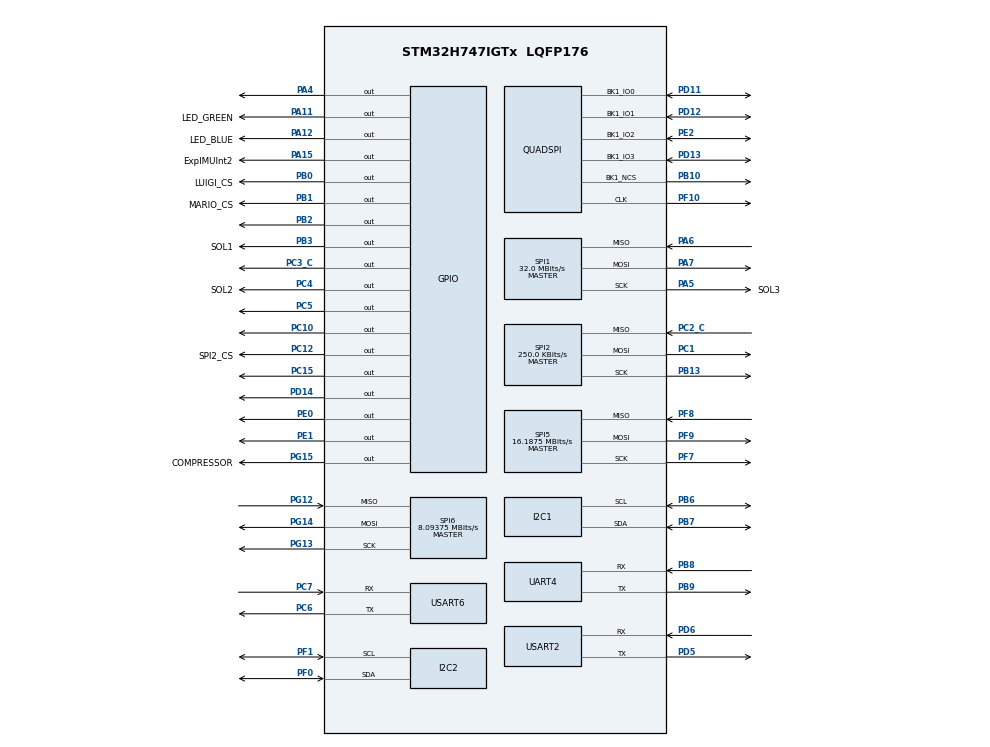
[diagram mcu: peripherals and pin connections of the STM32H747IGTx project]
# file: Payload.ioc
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CortexM4.IPs=BDMA,CORTEX_M4\:I,DEBUG,DMA,FATFS_M4\:I,FREERTOS_M4\:I,GPIO,IWDG2\:I,MDMA,NVIC2\:I,OPENAMP_M4\:I,PDM2PCM_M4\:I,PWR,RCC,RESMGR_UTILITY,SYS_M4\:I,USB_DEVICE_M4\:I,USB_HOST_M4\:I,VREFBUF,WWDG2\:I,QUADSPI,CRC
CortexM7.IPs=BDMA\:I,CORTEX_M7\:I,DEBUG\:I,DMA\:I,FATFS_M7\:I,FREERTOS_M7\:I,GPIO\:I,IWDG1\:I,MDMA\:I,NVIC1\:I,OPENAMP_M7\:I,PDM2PCM_M7\:I,PWR\:I,RCC\:I,RESMGR_UTILITY\:I,SYS\:I,USB_DEVICE_M7\:I,USB_HOST_M7\:I,VREFBUF\:I,WWDG1\:I,LPUART1\:I,USART2\:I,USART3\:I,USART6\:I,UART4\:I,UART5\:I,UART7\:I,SPI1\:I,SPI2\:I,SPI3\:I,SPI4\:I,SPI6\:I,QUADSPI\:I,I2C1\:I,I2C2\:I,I2C3\:I,SPI5\:I,CRC\:I,TIM1\:I
CortexM7.Pins=PC15-OSC32_OUT (OSC32_OUT),PC3_C,PA4,PC4,PC5,PB0,PB1,PB2,PD14,PA11,PA12,PA15 (JTDI),PC10,PC12,PG15,PB3 (JTDO/TRACESWO),PB4 (NJTRST),PB5,PE0,PE1
FREERTOS_M7.Tasks01=defaultTask,0,192,StartDefaultTask,Default,NULL,Dynamic,NULL,NULL
FREERTOS_M7.configMINIMAL_STACK_SIZE=192
FREERTOS_M7.configTOTAL_HEAP_SIZE=96000
FREERTOS_M7.configUSE_NEWLIB_REENTRANT=1
FREERTOS_M7.configUSE_TIMERS=1
I2C1.Timing=0x00807DBE
I2C2.Timing=0x00807DBE
Mcu.Family=STM32H7
Mcu.Name=STM32H747IGTx
Mcu.Package=LQFP176
NVIC1.PriorityGroup=NVIC_PRIORITYGROUP_4
NVIC1.TIM1_UP_IRQn=true\:15\:0\:false\:false\:true\:false\:false\:true\:true
NVIC1.TimeBase=TIM1_UP_IRQn
NVIC1.TimeBaseIP=TIM1
NVIC1.USART6_IRQn=true\:5\:0\:false\:false\:true\:true\:true\:true\:true
NVIC2.PriorityGroup=NVIC_PRIORITYGROUP_4
PA11.GPIO_Label=LED_GREEN
PA11.PinAttribute=CortexM7
PA11.Signal=GPIO_Output
PA12.GPIO_Label=LED_BLUE
PA12.PinAttribute=CortexM7
PA12.Signal=GPIO_Output
PA13\ (JTMS/SWDIO).PinAttribute=CortexM7
PA13\ (JTMS/SWDIO).Signal=DEBUG_JTMS-SWDIO
PA14\ (JTCK/SWCLK).PinAttribute=CortexM7
PA14\ (JTCK/SWCLK).Signal=DEBUG_JTCK-SWCLK
PA15\ (JTDI).GPIO_Label=ExpIMUInt2
PA15\ (JTDI).PinAttribute=CortexM7
PA15\ (JTDI).Signal=GPIO_Output
PA4.PinAttribute=CortexM7
PA4.Signal=GPIO_Output
PA5.GPIO_Label=SOL3
PA5.Mode=Full_Duplex_Master
PA5.PinAttribute=CortexM7
PA5.Signal=SPI1_SCK
PA6.Mode=Full_Duplex_Master
PA6.PinAttribute=CortexM7
PA6.Signal=SPI1_MISO
PA7.Mode=Full_Duplex_Master
PA7.PinAttribute=CortexM7
PA7.Signal=SPI1_MOSI
PB0.GPIO_Label=LUIGI_CS
PB0.PinAttribute=CortexM7
PB0.PinState=GPIO_PIN_SET
PB0.Signal=GPIO_Output
PB1.GPIO_Label=MARIO_CS
PB1.PinAttribute=CortexM7
PB1.PinState=GPIO_PIN_SET
PB1.Signal=GPIO_Output
PB10.Mode=Single Bank 1
PB10.PinAttribute=CortexM7
PB10.Signal=QUADSPI_BK1_NCS
PB13.Mode=Full_Duplex_Master
PB13.PinAttribute=CortexM7
PB13.Signal=SPI2_SCK
PB2.PinAttribute=CortexM7
PB2.Signal=GPIO_Output
PB3\ (JTDO/TRACESWO).GPIO_Label=SOL1
PB3\ (JTDO/TRACESWO).PinAttribute=CortexM7
PB3\ (JTDO/TRACESWO).Signal=GPIO_Output
PB6.Mode=I2C
PB6.PinAttribute=CortexM7
PB6.Signal=I2C1_SCL
PB7.Mode=I2C
PB7.PinAttribute=CortexM7
PB7.Signal=I2C1_SDA
PB8.Mode=Asynchronous
PB8.PinAttribute=CortexM7
PB8.Signal=UART4_RX
PB9.Mode=Asynchronous
PB9.PinAttribute=CortexM7
PB9.Signal=UART4_TX
PC1.Mode=Full_Duplex_Master
PC1.PinAttribute=CortexM7
PC1.Signal=SPI2_MOSI
PC10.PinAttribute=CortexM7
PC10.Signal=GPIO_Output
PC12.GPIO_Label=SPI2_CS
PC12.PinAttribute=CortexM7
PC12.Signal=GPIO_Output
PC15-OSC32_OUT\ (OSC32_OUT).PinAttribute=CortexM7
PC15-OSC32_OUT\ (OSC32_OUT).Signal=GPIO_Output
PC2_C.Mode=Full_Duplex_Master
PC2_C.PinAttribute=CortexM7
PC2_C.Signal=SPI2_MISO
PC3_C.PinAttribute=CortexM7
PC3_C.Signal=GPIO_Output
PC4.GPIO_Label=SOL2
PC4.PinAttribute=CortexM7
PC4.Signal=GPIO_Output
PC5.PinAttribute=CortexM7
PC5.Signal=GPIO_Output
PC6.Mode=Asynchronous
PC6.PinAttribute=CortexM7
PC6.Signal=USART6_TX
PC7.Mode=Asynchronous
PC7.PinAttribute=CortexM7
PC7.Signal=USART6_RX
PD11.Mode=Single Bank 1
PD11.PinAttribute=CortexM7
PD11.Signal=QUADSPI_BK1_IO0
PD12.Mode=Single Bank 1
PD12.PinAttribute=CortexM7
PD12.Signal=QUADSPI_BK1_IO1
PD13.Mode=Single Bank 1
PD13.PinAttribute=CortexM7
PD13.Signal=QUADSPI_BK1_IO3
PD14.PinAttribute=CortexM7
PD14.Signal=GPIO_Output
PD5.Mode=Asynchronous
PD5.PinAttribute=CortexM7
PD5.Signal=USART2_TX
PD6.Mode=Asynchronous
PD6.PinAttribute=CortexM7
PD6.Signal=USART2_RX
PE0.PinAttribute=CortexM7
PE0.Signal=GPIO_Output
PE1.PinAttribute=CortexM7
PE1.Signal=GPIO_Output
PE10.PinAttribute=CortexM7
PE10.Signal=QUADSPI_BK2_IO3
PE2.Mode=Single Bank 1
PE2.PinAttribute=CortexM7
PE2.Signal=QUADSPI_BK1_IO2
PE7.PinAttribute=CortexM7
PE7.Signal=QUADSPI_BK2_IO0
PE8.PinAttribute=CortexM7
PE8.Signal=QUADSPI_BK2_IO1
PE9.PinAttribute=CortexM7
PE9.Signal=QUADSPI_BK2_IO2
PF0.Mode=I2C
PF0.PinAttribute=CortexM7
PF0.Signal=I2C2_SDA
PF1.Mode=I2C
PF1.PinAttribute=CortexM7
PF1.Signal=I2C2_SCL
PF10.Mode=Single Bank 1
PF10.PinAttribute=CortexM7
PF10.Signal=QUADSPI_CLK
PF7.Mode=Full_Duplex_Master
PF7.PinAttribute=CortexM7
PF7.Signal=SPI5_SCK
PF8.Mode=Full_Duplex_Master
PF8.PinAttribute=CortexM7
PF8.Signal=SPI5_MISO
PF9.Mode=Full_Duplex_Master
PF9.PinAttribute=CortexM7
PF9.Signal=SPI5_MOSI
PG12.Mode=Full_Duplex_Master
PG12.PinAttribute=CortexM7
PG12.Signal=SPI6_MISO
PG13.Mode=Full_Duplex_Master
PG13.PinAttribute=CortexM7
PG13.Signal=SPI6_SCK
PG14.Mode=Full_Duplex_Master
PG14.PinAttribute=CortexM7
PG14.Signal=SPI6_MOSI
PG15.GPIO_Label=COMPRESSOR
PG15.PinAttribute=CortexM7
PG15.Signal=GPIO_Output
ProjectManager.HeapSize=M4-0x200,M7-0x200
ProjectManager.StackSize=M4-0x400,M7-0x400
ProjectManager.TargetToolchain=STM32CubeIDE
RCC.ADCFreq_Value=129000000
RCC.APB1Freq_Value=32375000
RCC.APB2Freq_Value=32375000
RCC.APB3Freq_Value=32375000
RCC.APB4Freq_Value=32375000
RCC.CortexFreq_Value=259000000
RCC.D1PPRE=RCC_APB3_DIV2
RCC.D2PPRE1=RCC_APB1_DIV2
RCC.D2PPRE2=RCC_APB2_DIV2
RCC.D3PPRE=RCC_APB4_DIV2
RCC.DIVM1=4
RCC.DIVN1=32
RCC.HCLKFreq_Value=64750000
RCC.HPRE=RCC_HCLK_DIV4
RCC.PLL1_VCI_Range-AdvancedSettings=RCC_PLL1VCIRANGE_1
RCC.PLL2FRACN=0
RCC.PLL3FRACN=0
RCC.PLLFRACN=3072
RCC.SPI123CLockSelection=RCC_SPI123CLKSOURCE_CLKP
RCC.SYSCLKFreq_VALUE=259000000
RCC.SYSCLKSource=RCC_SYSCLKSOURCE_PLLCLK
RCC.SupplySource=PWR_LDO_SUPPLY
RCC.USBFreq_Value=259000000
SPI1.BaudRatePrescaler=SPI_BAUDRATEPRESCALER_2
SPI1.CalculateBaudRate=32.0 MBits/s
SPI1.Direction=SPI_DIRECTION_2LINES
SPI1.Mode=SPI_MODE_MASTER
SPI1.VirtualType=VM_MASTER
SPI2.BaudRatePrescaler=SPI_BAUDRATEPRESCALER_256
SPI2.CLKPhase=SPI_PHASE_2EDGE
SPI2.CLKPolarity=SPI_POLARITY_HIGH
SPI2.CalculateBaudRate=250.0 KBits/s
SPI2.DataSize=SPI_DATASIZE_8BIT
SPI2.Direction=SPI_DIRECTION_2LINES
SPI2.Mode=SPI_MODE_MASTER
SPI2.VirtualType=VM_MASTER
SPI5.CalculateBaudRate=16.1875 MBits/s
SPI5.Direction=SPI_DIRECTION_2LINES
SPI5.Mode=SPI_MODE_MASTER
SPI5.VirtualType=VM_MASTER
SPI6.BaudRatePrescaler=SPI_BAUDRATEPRESCALER_4
SPI6.CLKPhase=SPI_PHASE_2EDGE
SPI6.CLKPolarity=SPI_POLARITY_HIGH
SPI6.CalculateBaudRate=8.09375 MBits/s
SPI6.DataSize=SPI_DATASIZE_8BIT
SPI6.Direction=SPI_DIRECTION_2LINES
SPI6.Mode=SPI_MODE_MASTER
SPI6.VirtualType=VM_MASTER
SYS.userName=SYS_M7
USART2.VirtualMode-Asynchronous=VM_ASYNC
USART6.VirtualMode-Asynchronous=VM_ASYNC
VP_CRC_VS_CRC.Mode=CRC_Activate
VP_FREERTOS_M7_VS_CMSIS_V1.Mode=CMSIS_V1
VP_SYS_M4_VS_Systick.Mode=SysTick
VP_SYS_VS_tim1.Mode=TIM1
board=custom

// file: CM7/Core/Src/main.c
/* USER CODE BEGIN Header */
/**
  ******************************************************************************
  * @file           : main.c
  * @brief          : Main program body
  ******************************************************************************
  * @attention
  *
  * Copyright (c) 2024 STMicroelectronics.
  * All rights reserved.
  *
  * This software is licensed under terms that can be found in the LICENSE file
  * in the root directory of this software component.
  * If no LICENSE file comes with this software, it is provided AS-IS.
  *
  ******************************************************************************
  */
/* USER CODE END Header */
#include "main.h"
#include "cmsis_os.h"

/* USER CODE BEGIN Includes */
#include "RunInterface.hpp"
/* USER CODE END Includes */

/* USER CODE BEGIN PD */

#ifndef HSEM_ID_0
#define HSEM_ID_0 (0U) /* HW semaphore 0*/
#endif

/* USER CODE END PD */

CRC_HandleTypeDef hcrc;

I2C_HandleTypeDef hi2c1;
I2C_HandleTypeDef hi2c2;

QSPI_HandleTypeDef hqspi;

SPI_HandleTypeDef hspi1;
SPI_HandleTypeDef hspi2;
SPI_HandleTypeDef hspi5;
SPI_HandleTypeDef hspi6;

UART_HandleTypeDef huart4;
UART_HandleTypeDef huart2;

osThreadId defaultTaskHandle;

void SystemClock_Config(void);
void PeriphCommonClock_Config(void);
static void MX_GPIO_Init(void);
static void MX_QUADSPI_Init(void);
static void MX_SPI1_Init(void);
static void MX_I2C1_Init(void);
static void MX_I2C2_Init(void);
static void MX_SPI2_Init(void);
static void MX_SPI5_Init(void);
static void MX_USART2_UART_Init(void);
static void MX_UART4_Init(void);
static void MX_USART6_UART_Init(void);
static void MX_SPI6_Init(void);
static void MX_CRC_Init(void);
void StartDefaultTask(void const * argument);

int main(void)
{

/* USER CODE BEGIN Boot_Mode_Sequence_0 */
  int32_t timeout;
/* USER CODE END Boot_Mode_Sequence_0 */

/* USER CODE BEGIN Boot_Mode_Sequence_1 */
  /* Wait until CPU2 boots and enters in stop mode or timeout*/
  timeout = 0xFFFF;
  while((__HAL_RCC_GET_FLAG(RCC_FLAG_D2CKRDY) != RESET) && (timeout-- > 0));
  if ( timeout < 0 )
  {
  Error_Handler();
  }
/* USER CODE END Boot_Mode_Sequence_1 */
  /* MCU Configuration--------------------------------------------------------*/

  /* Reset of all peripherals, Initializes the Flash interface and the Systick. */
  HAL_Init();

  /* Configure the system clock */
  SystemClock_Config();

/* Configure the peripherals common clocks */
  PeriphCommonClock_Config();
/* USER CODE BEGIN Boot_Mode_Sequence_2 */
/* When system initialization is finished, Cortex-M7 will release Cortex-M4 by means of
HSEM notification */
/*HW semaphore Clock enable*/
__HAL_RCC_HSEM_CLK_ENABLE();
/*Take HSEM */
HAL_HSEM_FastTake(HSEM_ID_0);
/*Release HSEM in order to notify the CPU2(CM4)*/
HAL_HSEM_Release(HSEM_ID_0,0);
/* wait until CPU2 wakes up from stop mode */
timeout = 0xFFFF;
while((__HAL_RCC_GET_FLAG(RCC_FLAG_D2CKRDY) == RESET) && (timeout-- > 0));
if ( timeout < 0 )
{
Error_Handler();
}
/* USER CODE END Boot_Mode_Sequence_2 */

  /* Initialize all configured peripherals */
  MX_GPIO_Init();
  MX_QUADSPI_Init();
  MX_SPI1_Init();
  MX_I2C1_Init();
  MX_I2C2_Init();
  MX_SPI2_Init();
  MX_SPI5_Init();
  MX_USART2_UART_Init();
  MX_UART4_Init();
  MX_USART6_UART_Init();
  MX_SPI6_Init();
  MX_CRC_Init();
  /* USER CODE BEGIN 2 */
  run_interface();
  #if 0
  /* USER CODE END 2 */

  /* Create the thread(s) */
  /* definition and creation of defaultTask */
  osThreadDef(defaultTask, StartDefaultTask, osPriorityNormal, 0, 192);
  defaultTaskHandle = osThreadCreate(osThread(defaultTask), NULL);

  /* Start scheduler */
  osKernelStart();

  /* We should never get here as control is now taken by the scheduler */

  /* Infinite loop */
  while (1)
  {

    /* USER CODE BEGIN 3 */
  }
#endif
  /* USER CODE END 3 */
}

void SystemClock_Config(void)
{
  RCC_OscInitTypeDef RCC_OscInitStruct = {0};
  RCC_ClkInitTypeDef RCC_ClkInitStruct = {0};

  /** Supply configuration update enable
  */
  HAL_PWREx_ConfigSupply(PWR_LDO_SUPPLY);

  /** Configure the main internal regulator output voltage
  */
  __HAL_PWR_VOLTAGESCALING_CONFIG(PWR_REGULATOR_VOLTAGE_SCALE2);

  while(!__HAL_PWR_GET_FLAG(PWR_FLAG_VOSRDY)) {}

  /** Initializes the RCC Oscillators according to the specified parameters
  * in the RCC_OscInitTypeDef structure.
  */
  RCC_OscInitStruct.OscillatorType = RCC_OSCILLATORTYPE_HSI;
  RCC_OscInitStruct.HSIState = RCC_HSI_DIV1;
  RCC_OscInitStruct.HSICalibrationValue = RCC_HSICALIBRATION_DEFAULT;
  RCC_OscInitStruct.PLL.PLLState = RCC_PLL_ON;
  RCC_OscInitStruct.PLL.PLLSource = RCC_PLLSOURCE_HSI;
  RCC_OscInitStruct.PLL.PLLM = 4;
  RCC_OscInitStruct.PLL.PLLN = 32;
  RCC_OscInitStruct.PLL.PLLP = 2;
  RCC_OscInitStruct.PLL.PLLQ = 2;
  RCC_OscInitStruct.PLL.PLLR = 2;
  RCC_OscInitStruct.PLL.PLLRGE = RCC_PLL1VCIRANGE_3;
  RCC_OscInitStruct.PLL.PLLVCOSEL = RCC_PLL1VCOWIDE;
  RCC_OscInitStruct.PLL.PLLFRACN = 3072;
  if (HAL_RCC_OscConfig(&RCC_OscInitStruct) != HAL_OK)
  {
    Error_Handler();
  }

  /** Initializes the CPU, AHB and APB buses clocks
  */
  RCC_ClkInitStruct.ClockType = RCC_CLOCKTYPE_HCLK|RCC_CLOCKTYPE_SYSCLK
                              |RCC_CLOCKTYPE_PCLK1|RCC_CLOCKTYPE_PCLK2
                              |RCC_CLOCKTYPE_D3PCLK1|RCC_CLOCKTYPE_D1PCLK1;
  RCC_ClkInitStruct.SYSCLKSource = RCC_SYSCLKSOURCE_PLLCLK;
  RCC_ClkInitStruct.SYSCLKDivider = RCC_SYSCLK_DIV1;
  RCC_ClkInitStruct.AHBCLKDivider = RCC_HCLK_DIV4;
  RCC_ClkInitStruct.APB3CLKDivider = RCC_APB3_DIV2;
  RCC_ClkInitStruct.APB1CLKDivider = RCC_APB1_DIV2;
  RCC_ClkInitStruct.APB2CLKDivider = RCC_APB2_DIV2;
  RCC_ClkInitStruct.APB4CLKDivider = RCC_APB4_DIV2;

  if (HAL_RCC_ClockConfig(&RCC_ClkInitStruct, FLASH_LATENCY_1) != HAL_OK)
  {
    Error_Handler();
  }
}

void PeriphCommonClock_Config(void)
{
  RCC_PeriphCLKInitTypeDef PeriphClkInitStruct = {0};

  /** Initializes the peripherals clock
  */
  PeriphClkInitStruct.PeriphClockSelection = RCC_PERIPHCLK_CKPER;
  PeriphClkInitStruct.CkperClockSelection = RCC_CLKPSOURCE_HSI;
  if (HAL_RCCEx_PeriphCLKConfig(&PeriphClkInitStruct) != HAL_OK)
  {
    Error_Handler();
  }
}

static void MX_CRC_Init(void)
{

  hcrc.Instance = CRC;
  hcrc.Init.DefaultPolynomialUse = DEFAULT_POLYNOMIAL_ENABLE;
  hcrc.Init.DefaultInitValueUse = DEFAULT_INIT_VALUE_ENABLE;
  hcrc.Init.InputDataInversionMode = CRC_INPUTDATA_INVERSION_NONE;
  hcrc.Init.OutputDataInversionMode = CRC_OUTPUTDATA_INVERSION_DISABLE;
  hcrc.InputDataFormat = CRC_INPUTDATA_FORMAT_BYTES;
  if (HAL_CRC_Init(&hcrc) != HAL_OK)
  {
    Error_Handler();
  }

}

static void MX_I2C1_Init(void)
{

  hi2c1.Instance = I2C1;
  hi2c1.Init.Timing = 0x00807DBE;
  hi2c1.Init.OwnAddress1 = 0;
  hi2c1.Init.AddressingMode = I2C_ADDRESSINGMODE_7BIT;
  hi2c1.Init.DualAddressMode = I2C_DUALADDRESS_DISABLE;
  hi2c1.Init.OwnAddress2 = 0;
  hi2c1.Init.OwnAddress2Masks = I2C_OA2_NOMASK;
  hi2c1.Init.GeneralCallMode = I2C_GENERALCALL_DISABLE;
  hi2c1.Init.NoStretchMode = I2C_NOSTRETCH_DISABLE;
  if (HAL_I2C_Init(&hi2c1) != HAL_OK)
  {
    Error_Handler();
  }

  /** Configure Analogue filter
  */
  if (HAL_I2CEx_ConfigAnalogFilter(&hi2c1, I2C_ANALOGFILTER_ENABLE) != HAL_OK)
  {
    Error_Handler();
  }

  /** Configure Digital filter
  */
  if (HAL_I2CEx_ConfigDigitalFilter(&hi2c1, 0) != HAL_OK)
  {
    Error_Handler();
  }

}

static void MX_I2C2_Init(void)
{

  hi2c2.Instance = I2C2;
  hi2c2.Init.Timing = 0x00807DBE;
  hi2c2.Init.OwnAddress1 = 0;
  hi2c2.Init.AddressingMode = I2C_ADDRESSINGMODE_7BIT;
  hi2c2.Init.DualAddressMode = I2C_DUALADDRESS_DISABLE;
  hi2c2.Init.OwnAddress2 = 0;
  hi2c2.Init.OwnAddress2Masks = I2C_OA2_NOMASK;
  hi2c2.Init.GeneralCallMode = I2C_GENERALCALL_DISABLE;
  hi2c2.Init.NoStretchMode = I2C_NOSTRETCH_DISABLE;
  if (HAL_I2C_Init(&hi2c2) != HAL_OK)
  {
    Error_Handler();
  }

  /** Configure Analogue filter
  */
  if (HAL_I2CEx_ConfigAnalogFilter(&hi2c2, I2C_ANALOGFILTER_ENABLE) != HAL_OK)
  {
    Error_Handler();
  }

  /** Configure Digital filter
  */
  if (HAL_I2CEx_ConfigDigitalFilter(&hi2c2, 0) != HAL_OK)
  {
    Error_Handler();
  }

}

static void MX_QUADSPI_Init(void)
{

  /* QUADSPI parameter configuration*/
  hqspi.Instance = QUADSPI;
  hqspi.Init.ClockPrescaler = 255;
  hqspi.Init.FifoThreshold = 1;
  hqspi.Init.SampleShifting = QSPI_SAMPLE_SHIFTING_NONE;
  hqspi.Init.FlashSize = 1;
  hqspi.Init.ChipSelectHighTime = QSPI_CS_HIGH_TIME_1_CYCLE;
  hqspi.Init.ClockMode = QSPI_CLOCK_MODE_0;
  hqspi.Init.FlashID = QSPI_FLASH_ID_1;
  hqspi.Init.DualFlash = QSPI_DUALFLASH_DISABLE;
  if (HAL_QSPI_Init(&hqspi) != HAL_OK)
  {
    Error_Handler();
  }

}

static void MX_SPI1_Init(void)
{

  /* SPI1 parameter configuration*/
  hspi1.Instance = SPI1;
  hspi1.Init.Mode = SPI_MODE_MASTER;
  hspi1.Init.Direction = SPI_DIRECTION_2LINES;
  hspi1.Init.DataSize = SPI_DATASIZE_4BIT;
  hspi1.Init.CLKPolarity = SPI_POLARITY_LOW;
  hspi1.Init.CLKPhase = SPI_PHASE_1EDGE;
  hspi1.Init.NSS = SPI_NSS_SOFT;
  hspi1.Init.BaudRatePrescaler = SPI_BAUDRATEPRESCALER_2;
  hspi1.Init.FirstBit = SPI_FIRSTBIT_MSB;
  hspi1.Init.TIMode = SPI_TIMODE_DISABLE;
  hspi1.Init.CRCCalculation = SPI_CRCCALCULATION_DISABLE;
  hspi1.Init.CRCPolynomial = 0x0;
  hspi1.Init.NSSPMode = SPI_NSS_PULSE_ENABLE;
  hspi1.Init.NSSPolarity = SPI_NSS_POLARITY_LOW;
  hspi1.Init.FifoThreshold = SPI_FIFO_THRESHOLD_01DATA;
  hspi1.Init.TxCRCInitializationPattern = SPI_CRC_INITIALIZATION_ALL_ZERO_PATTERN;
  hspi1.Init.RxCRCInitializationPattern = SPI_CRC_INITIALIZATION_ALL_ZERO_PATTERN;
  hspi1.Init.MasterSSIdleness = SPI_MASTER_SS_IDLENESS_00CYCLE;
  hspi1.Init.MasterInterDataIdleness = SPI_MASTER_INTERDATA_IDLENESS_00CYCLE;
  hspi1.Init.MasterReceiverAutoSusp = SPI_MASTER_RX_AUTOSUSP_DISABLE;
  hspi1.Init.MasterKeepIOState = SPI_MASTER_KEEP_IO_STATE_DISABLE;
  hspi1.Init.IOSwap = SPI_IO_SWAP_DISABLE;
  if (HAL_SPI_Init(&hspi1) != HAL_OK)
  {
    Error_Handler();
  }

}

static void MX_SPI2_Init(void)
{

  /* SPI2 parameter configuration*/
  hspi2.Instance = SPI2;
  hspi2.Init.Mode = SPI_MODE_MASTER;
  hspi2.Init.Direction = SPI_DIRECTION_2LINES;
  hspi2.Init.DataSize = SPI_DATASIZE_8BIT;
  hspi2.Init.CLKPolarity = SPI_POLARITY_HIGH;
  hspi2.Init.CLKPhase = SPI_PHASE_2EDGE;
  hspi2.Init.NSS = SPI_NSS_SOFT;
  hspi2.Init.BaudRatePrescaler = SPI_BAUDRATEPRESCALER_256;
  hspi2.Init.FirstBit = SPI_FIRSTBIT_MSB;
  hspi2.Init.TIMode = SPI_TIMODE_DISABLE;
  hspi2.Init.CRCCalculation = SPI_CRCCALCULATION_DISABLE;
  hspi2.Init.CRCPolynomial = 0x0;
  hspi2.Init.NSSPMode = SPI_NSS_PULSE_ENABLE;
  hspi2.Init.NSSPolarity = SPI_NSS_POLARITY_LOW;
  hspi2.Init.FifoThreshold = SPI_FIFO_THRESHOLD_01DATA;
  hspi2.Init.TxCRCInitializationPattern = SPI_CRC_INITIALIZATION_ALL_ZERO_PATTERN;
  hspi2.Init.RxCRCInitializationPattern = SPI_CRC_INITIALIZATION_ALL_ZERO_PATTERN;
  hspi2.Init.MasterSSIdleness = SPI_MASTER_SS_IDLENESS_00CYCLE;
  hspi2.Init.MasterInterDataIdleness = SPI_MASTER_INTERDATA_IDLENESS_00CYCLE;
  hspi2.Init.MasterReceiverAutoSusp = SPI_MASTER_RX_AUTOSUSP_DISABLE;
  hspi2.Init.MasterKeepIOState = SPI_MASTER_KEEP_IO_STATE_DISABLE;
  hspi2.Init.IOSwap = SPI_IO_SWAP_DISABLE;
  if (HAL_SPI_Init(&hspi2) != HAL_OK)
  {
    Error_Handler();
  }

}

static void MX_SPI5_Init(void)
{

  /* SPI5 parameter configuration*/
  hspi5.Instance = SPI5;
  hspi5.Init.Mode = SPI_MODE_MASTER;
  hspi5.Init.Direction = SPI_DIRECTION_2LINES;
  hspi5.Init.DataSize = SPI_DATASIZE_4BIT;
  hspi5.Init.CLKPolarity = SPI_POLARITY_LOW;
  hspi5.Init.CLKPhase = SPI_PHASE_1EDGE;
  hspi5.Init.NSS = SPI_NSS_SOFT;
  hspi5.Init.BaudRatePrescaler = SPI_BAUDRATEPRESCALER_2;
  hspi5.Init.FirstBit = SPI_FIRSTBIT_MSB;
  hspi5.Init.TIMode = SPI_TIMODE_DISABLE;
  hspi5.Init.CRCCalculation = SPI_CRCCALCULATION_DISABLE;
  hspi5.Init.CRCPolynomial = 0x0;
  hspi5.Init.NSSPMode = SPI_NSS_PULSE_ENABLE;
  hspi5.Init.NSSPolarity = SPI_NSS_POLARITY_LOW;
  hspi5.Init.FifoThreshold = SPI_FIFO_THRESHOLD_01DATA;
  hspi5.Init.TxCRCInitializationPattern = SPI_CRC_INITIALIZATION_ALL_ZERO_PATTERN;
  hspi5.Init.RxCRCInitializationPattern = SPI_CRC_INITIALIZATION_ALL_ZERO_PATTERN;
  hspi5.Init.MasterSSIdleness = SPI_MASTER_SS_IDLENESS_00CYCLE;
  hspi5.Init.MasterInterDataIdleness = SPI_MASTER_INTERDATA_IDLENESS_00CYCLE;
  hspi5.Init.MasterReceiverAutoSusp = SPI_MASTER_RX_AUTOSUSP_DISABLE;
  hspi5.Init.MasterKeepIOState = SPI_MASTER_KEEP_IO_STATE_DISABLE;
  hspi5.Init.IOSwap = SPI_IO_SWAP_DISABLE;
  if (HAL_SPI_Init(&hspi5) != HAL_OK)
  {
    Error_Handler();
  }

}

static void MX_SPI6_Init(void)
{

  /* SPI6 parameter configuration*/
  hspi6.Instance = SPI6;
  hspi6.Init.Mode = SPI_MODE_MASTER;
  hspi6.Init.Direction = SPI_DIRECTION_2LINES;
  hspi6.Init.DataSize = SPI_DATASIZE_8BIT;
  hspi6.Init.CLKPolarity = SPI_POLARITY_HIGH;
  hspi6.Init.CLKPhase = SPI_PHASE_2EDGE;
  hspi6.Init.NSS = SPI_NSS_SOFT;
  hspi6.Init.BaudRatePrescaler = SPI_BAUDRATEPRESCALER_4;
  hspi6.Init.FirstBit = SPI_FIRSTBIT_MSB;
  hspi6.Init.TIMode = SPI_TIMODE_DISABLE;
  hspi6.Init.CRCCalculation = SPI_CRCCALCULATION_DISABLE;
  hspi6.Init.CRCPolynomial = 0x0;
  hspi6.Init.NSSPMode = SPI_NSS_PULSE_ENABLE;
  hspi6.Init.NSSPolarity = SPI_NSS_POLARITY_LOW;
  hspi6.Init.FifoThreshold = SPI_FIFO_THRESHOLD_01DATA;
  hspi6.Init.TxCRCInitializationPattern = SPI_CRC_INITIALIZATION_ALL_ZERO_PATTERN;
  hspi6.Init.RxCRCInitializationPattern = SPI_CRC_INITIALIZATION_ALL_ZERO_PATTERN;
  hspi6.Init.MasterSSIdleness = SPI_MASTER_SS_IDLENESS_00CYCLE;
  hspi6.Init.MasterInterDataIdleness = SPI_MASTER_INTERDATA_IDLENESS_00CYCLE;
  hspi6.Init.MasterReceiverAutoSusp = SPI_MASTER_RX_AUTOSUSP_DISABLE;
  hspi6.Init.MasterKeepIOState = SPI_MASTER_KEEP_IO_STATE_DISABLE;
  hspi6.Init.IOSwap = SPI_IO_SWAP_DISABLE;
  if (HAL_SPI_Init(&hspi6) != HAL_OK)
  {
    Error_Handler();
  }

}

static void MX_UART4_Init(void)
{

  huart4.Instance = UART4;
  huart4.Init.BaudRate = 115200;
  huart4.Init.WordLength = UART_WORDLENGTH_8B;
  huart4.Init.StopBits = UART_STOPBITS_1;
  huart4.Init.Parity = UART_PARITY_NONE;
  huart4.Init.Mode = UART_MODE_TX_RX;
  huart4.Init.HwFlowCtl = UART_HWCONTROL_NONE;
  huart4.Init.OverSampling = UART_OVERSAMPLING_16;
  huart4.Init.OneBitSampling = UART_ONE_BIT_SAMPLE_DISABLE;
  huart4.Init.ClockPrescaler = UART_PRESCALER_DIV1;
  huart4.AdvancedInit.AdvFeatureInit = UART_ADVFEATURE_NO_INIT;
  if (HAL_UART_Init(&huart4) != HAL_OK)
  {
    Error_Handler();
  }
  if (HAL_UARTEx_SetTxFifoThreshold(&huart4, UART_TXFIFO_THRESHOLD_1_8) != HAL_OK)
  {
    Error_Handler();
  }
  if (HAL_UARTEx_SetRxFifoThreshold(&huart4, UART_RXFIFO_THRESHOLD_1_8) != HAL_OK)
  {
    Error_Handler();
  }
  if (HAL_UARTEx_DisableFifoMode(&huart4) != HAL_OK)
  {
    Error_Handler();
  }

}

static void MX_USART2_UART_Init(void)
{

  huart2.Instance = USART2;
  huart2.Init.BaudRate = 115200;
  huart2.Init.WordLength = UART_WORDLENGTH_8B;
  huart2.Init.StopBits = UART_STOPBITS_1;
  huart2.Init.Parity = UART_PARITY_NONE;
  huart2.Init.Mode = UART_MODE_TX_RX;
  huart2.Init.HwFlowCtl = UART_HWCONTROL_NONE;
  huart2.Init.OverSampling = UART_OVERSAMPLING_16;
  huart2.Init.OneBitSampling = UART_ONE_BIT_SAMPLE_DISABLE;
  huart2.Init.ClockPrescaler = UART_PRESCALER_DIV1;
  huart2.AdvancedInit.AdvFeatureInit = UART_ADVFEATURE_NO_INIT;
  if (HAL_UART_Init(&huart2) != HAL_OK)
  {
    Error_Handler();
  }
  if (HAL_UARTEx_SetTxFifoThreshold(&huart2, UART_TXFIFO_THRESHOLD_1_8) != HAL_OK)
  {
    Error_Handler();
  }
  if (HAL_UARTEx_SetRxFifoThreshold(&huart2, UART_RXFIFO_THRESHOLD_1_8) != HAL_OK)
  {
    Error_Handler();
  }
  if (HAL_UARTEx_DisableFifoMode(&huart2) != HAL_OK)
  {
    Error_Handler();
  }

}

static void MX_USART6_UART_Init(void)
{

  LL_USART_InitTypeDef USART_InitStruct = {0};

  LL_GPIO_InitTypeDef GPIO_InitStruct = {0};
  RCC_PeriphCLKInitTypeDef PeriphClkInitStruct = {0};

  /** Initializes the peripherals clock
  */
  PeriphClkInitStruct.PeriphClockSelection = RCC_PERIPHCLK_USART6;
  PeriphClkInitStruct.Usart16ClockSelection = RCC_USART16CLKSOURCE_D2PCLK2;
  if (HAL_RCCEx_PeriphCLKConfig(&PeriphClkInitStruct) != HAL_OK)
  {
    Error_Handler();
  }

  /* Peripheral clock enable */
  LL_APB2_GRP1_EnableClock(LL_APB2_GRP1_PERIPH_USART6);

  LL_AHB4_GRP1_EnableClock(LL_AHB4_GRP1_PERIPH_GPIOC);
  /**USART6 GPIO Configuration
  PC6   ------> USART6_TX
  PC7   ------> USART6_RX
  */
  GPIO_InitStruct.Pin = LL_GPIO_PIN_6|LL_GPIO_PIN_7;
  GPIO_InitStruct.Mode = LL_GPIO_MODE_ALTERNATE;
  GPIO_InitStruct.Speed = LL_GPIO_SPEED_FREQ_LOW;
  GPIO_InitStruct.OutputType = LL_GPIO_OUTPUT_PUSHPULL;
  GPIO_InitStruct.Pull = LL_GPIO_PULL_NO;
  GPIO_InitStruct.Alternate = LL_GPIO_AF_7;
  LL_GPIO_Init(GPIOC, &GPIO_InitStruct);

  /* USART6 interrupt Init */
  NVIC_SetPriority(USART6_IRQn, NVIC_EncodePriority(NVIC_GetPriorityGrouping(),5, 0));
  NVIC_EnableIRQ(USART6_IRQn);

  USART_InitStruct.PrescalerValue = LL_USART_PRESCALER_DIV1;
  USART_InitStruct.BaudRate = 115200;
  USART_InitStruct.DataWidth = LL_USART_DATAWIDTH_8B;
  USART_InitStruct.StopBits = LL_USART_STOPBITS_1;
  USART_InitStruct.Parity = LL_USART_PARITY_NONE;
  USART_InitStruct.TransferDirection = LL_USART_DIRECTION_TX_RX;
  USART_InitStruct.HardwareFlowControl = LL_USART_HWCONTROL_NONE;
  USART_InitStruct.OverSampling = LL_USART_OVERSAMPLING_16;
  LL_USART_Init(USART6, &USART_InitStruct);
  LL_USART_SetTXFIFOThreshold(USART6, LL_USART_FIFOTHRESHOLD_1_8);
  LL_USART_SetRXFIFOThreshold(USART6, LL_USART_FIFOTHRESHOLD_1_8);
  LL_USART_DisableFIFO(USART6);
  LL_USART_ConfigAsyncMode(USART6);

  LL_USART_Enable(USART6);

  /* Polling USART6 initialisation */
  while((!(LL_USART_IsActiveFlag_TEACK(USART6))) || (!(LL_USART_IsActiveFlag_REACK(USART6))))
  {
  }

}

static void MX_GPIO_Init(void)
{
  GPIO_InitTypeDef GPIO_InitStruct = {0};

  /* GPIO Ports Clock Enable */
  __HAL_RCC_GPIOE_CLK_ENABLE();
  __HAL_RCC_GPIOC_CLK_ENABLE();
  __HAL_RCC_GPIOF_CLK_ENABLE();
  __HAL_RCC_GPIOA_CLK_ENABLE();
  __HAL_RCC_GPIOB_CLK_ENABLE();
  __HAL_RCC_GPIOD_CLK_ENABLE();
  __HAL_RCC_GPIOG_CLK_ENABLE();

  /*Configure GPIO pin Output Level */
  HAL_GPIO_WritePin(GPIOC, GPIO_PIN_15|GPIO_PIN_3|SOL2_Pin|GPIO_PIN_5
                          |GPIO_PIN_10|SPI2_CS_Pin, GPIO_PIN_RESET);

  /*Configure GPIO pin Output Level */
  HAL_GPIO_WritePin(GPIOA, GPIO_PIN_4|LED_GREEN_Pin|LED_BLUE_Pin|ExpIMUInt2_Pin, GPIO_PIN_RESET);

  /*Configure GPIO pin Output Level */
  HAL_GPIO_WritePin(GPIOB, LUIGI_CS_Pin|MARIO_CS_Pin, GPIO_PIN_SET);

  /*Configure GPIO pin Output Level */
  HAL_GPIO_WritePin(GPIOB, GPIO_PIN_2|SOL1_Pin, GPIO_PIN_RESET);

  /*Configure GPIO pin Output Level */
  HAL_GPIO_WritePin(GPIOD, GPIO_PIN_14, GPIO_PIN_RESET);

  /*Configure GPIO pin Output Level */
  HAL_GPIO_WritePin(COMPRESSOR_GPIO_Port, COMPRESSOR_Pin, GPIO_PIN_RESET);

  /*Configure GPIO pin Output Level */
  HAL_GPIO_WritePin(GPIOE, GPIO_PIN_0|GPIO_PIN_1, GPIO_PIN_RESET);

  /*Configure GPIO pins : PC15 PC3 SOL2_Pin PC5
                           PC10 SPI2_CS_Pin */
  GPIO_InitStruct.Pin = GPIO_PIN_15|GPIO_PIN_3|SOL2_Pin|GPIO_PIN_5
                          |GPIO_PIN_10|SPI2_CS_Pin;
  GPIO_InitStruct.Mode = GPIO_MODE_OUTPUT_PP;
  GPIO_InitStruct.Pull = GPIO_NOPULL;
  GPIO_InitStruct.Speed = GPIO_SPEED_FREQ_LOW;
  HAL_GPIO_Init(GPIOC, &GPIO_InitStruct);

  /*Configure GPIO pins : PA4 LED_GREEN_Pin LED_BLUE_Pin ExpIMUInt2_Pin */
  GPIO_InitStruct.Pin = GPIO_PIN_4|LED_GREEN_Pin|LED_BLUE_Pin|ExpIMUInt2_Pin;
  GPIO_InitStruct.Mode = GPIO_MODE_OUTPUT_PP;
  GPIO_InitStruct.Pull = GPIO_NOPULL;
  GPIO_InitStruct.Speed = GPIO_SPEED_FREQ_LOW;
  HAL_GPIO_Init(GPIOA, &GPIO_InitStruct);

  /*Configure GPIO pins : LUIGI_CS_Pin MARIO_CS_Pin PB2 SOL1_Pin */
  GPIO_InitStruct.Pin = LUIGI_CS_Pin|MARIO_CS_Pin|GPIO_PIN_2|SOL1_Pin;
  GPIO_InitStruct.Mode = GPIO_MODE_OUTPUT_PP;
  GPIO_InitStruct.Pull = GPIO_NOPULL;
  GPIO_InitStruct.Speed = GPIO_SPEED_FREQ_LOW;
  HAL_GPIO_Init(GPIOB, &GPIO_InitStruct);

  /*Configure GPIO pin : PD14 */
  GPIO_InitStruct.Pin = GPIO_PIN_14;
  GPIO_InitStruct.Mode = GPIO_MODE_OUTPUT_PP;
  GPIO_InitStruct.Pull = GPIO_NOPULL;
  GPIO_InitStruct.Speed = GPIO_SPEED_FREQ_LOW;
  HAL_GPIO_Init(GPIOD, &GPIO_InitStruct);

  /*Configure GPIO pin : COMPRESSOR_Pin */
  GPIO_InitStruct.Pin = COMPRESSOR_Pin;
  GPIO_InitStruct.Mode = GPIO_MODE_OUTPUT_PP;
  GPIO_InitStruct.Pull = GPIO_NOPULL;
  GPIO_InitStruct.Speed = GPIO_SPEED_FREQ_LOW;
  HAL_GPIO_Init(COMPRESSOR_GPIO_Port, &GPIO_InitStruct);

  /*Configure GPIO pins : PE0 PE1 */
  GPIO_InitStruct.Pin = GPIO_PIN_0|GPIO_PIN_1;
  GPIO_InitStruct.Mode = GPIO_MODE_OUTPUT_PP;
  GPIO_InitStruct.Pull = GPIO_NOPULL;
  GPIO_InitStruct.Speed = GPIO_SPEED_FREQ_LOW;
  HAL_GPIO_Init(GPIOE, &GPIO_InitStruct);

}

void StartDefaultTask(void const * argument)
{
  for(;;)
  {
    osDelay(1);
  }
}

void HAL_TIM_PeriodElapsedCallback(TIM_HandleTypeDef *htim)
{
  if (htim->Instance == TIM1) {
    HAL_IncTick();
  }
}

void Error_Handler(void)
{
  __disable_irq();
  while (1)
  {
  }
}

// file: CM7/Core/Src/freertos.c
/* USER CODE BEGIN Header */
/**
  ******************************************************************************
  * File Name          : freertos.c
  * Description        : Code for freertos applications
  ******************************************************************************
  * @attention
  *
  * Copyright (c) 2024 STMicroelectronics.
  * All rights reserved.
  *
  * This software is licensed under terms that can be found in the LICENSE file
  * in the root directory of this software component.
  * If no LICENSE file comes with this software, it is provided AS-IS.
  *
  ******************************************************************************
  */
/* USER CODE END Header */

#include "FreeRTOS.h"
#include "task.h"
#include "main.h"

/* GetIdleTaskMemory prototype (linked to static allocation support) */
void vApplicationGetIdleTaskMemory( StaticTask_t **ppxIdleTaskTCBBuffer, StackType_t **ppxIdleTaskStackBuffer, uint32_t *pulIdleTaskStackSize );

/* GetTimerTaskMemory prototype (linked to static allocation support) */
void vApplicationGetTimerTaskMemory( StaticTask_t **ppxTimerTaskTCBBuffer, StackType_t **ppxTimerTaskStackBuffer, uint32_t *pulTimerTaskStackSize );

/* USER CODE BEGIN GET_IDLE_TASK_MEMORY */
static StaticTask_t xIdleTaskTCBBuffer;
static StackType_t xIdleStack[configMINIMAL_STACK_SIZE];

void vApplicationGetIdleTaskMemory( StaticTask_t **ppxIdleTaskTCBBuffer, StackType_t **ppxIdleTaskStackBuffer, uint32_t *pulIdleTaskStackSize )
{
  *ppxIdleTaskTCBBuffer = &xIdleTaskTCBBuffer;
  *ppxIdleTaskStackBuffer = &xIdleStack[0];
  *pulIdleTaskStackSize = configMINIMAL_STACK_SIZE;
  /* place for user code */
}
/* USER CODE END GET_IDLE_TASK_MEMORY */

/* USER CODE BEGIN GET_TIMER_TASK_MEMORY */
static StaticTask_t xTimerTaskTCBBuffer;
static StackType_t xTimerStack[configTIMER_TASK_STACK_DEPTH];

void vApplicationGetTimerTaskMemory( StaticTask_t **ppxTimerTaskTCBBuffer, StackType_t **ppxTimerTaskStackBuffer, uint32_t *pulTimerTaskStackSize )
{
  *ppxTimerTaskTCBBuffer = &xTimerTaskTCBBuffer;
  *ppxTimerTaskStackBuffer = &xTimerStack[0];
  *pulTimerTaskStackSize = configTIMER_TASK_STACK_DEPTH;
  /* place for user code */
}
/* USER CODE END GET_TIMER_TASK_MEMORY */
